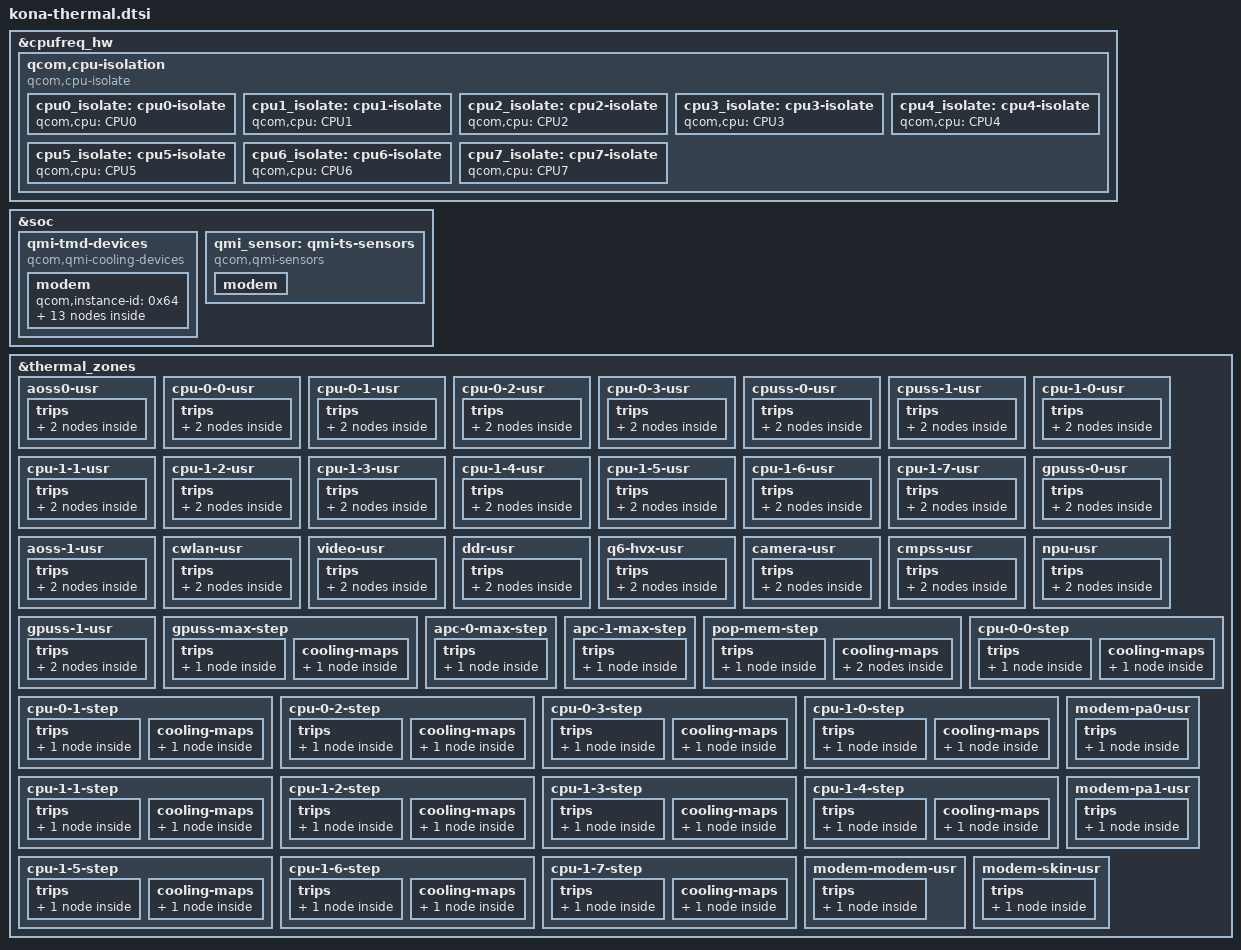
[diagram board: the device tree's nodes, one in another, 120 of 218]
// SPDX-License-Identifier: GPL-2.0-only
/*
 * Copyright (c) 2018-2019, The Linux Foundation. All rights reserved.
 */

#include <dt-bindings/thermal/thermal.h>

&cpufreq_hw {
	qcom,cpu-isolation {
		compatible = "qcom,cpu-isolate";
		cpu0_isolate: cpu0-isolate {
			qcom,cpu = <&CPU0>;
			#cooling-cells = <2>;
		};

		cpu1_isolate: cpu1-isolate {
			qcom,cpu = <&CPU1>;
			#cooling-cells = <2>;
		};

		cpu2_isolate: cpu2-isolate {
			qcom,cpu = <&CPU2>;
			#cooling-cells = <2>;
		};

		cpu3_isolate: cpu3-isolate {
			qcom,cpu = <&CPU3>;
			#cooling-cells = <2>;
		};

		cpu4_isolate: cpu4-isolate {
			qcom,cpu = <&CPU4>;
			#cooling-cells = <2>;
		};

		cpu5_isolate: cpu5-isolate {
			qcom,cpu = <&CPU5>;
			#cooling-cells = <2>;
		};

		cpu6_isolate: cpu6-isolate {
			qcom,cpu = <&CPU6>;
			#cooling-cells = <2>;
		};

		cpu7_isolate: cpu7-isolate {
			qcom,cpu = <&CPU7>;
			#cooling-cells = <2>;
		};
	};
};

&soc {
	qmi-tmd-devices {
		compatible = "qcom,qmi-cooling-devices";

		modem {
			qcom,instance-id = <0x64>;

			modem_pa: modem_pa {
				qcom,qmi-dev-name = "pa";
				#cooling-cells = <2>;
			};

			modem_proc: modem_proc {
				qcom,qmi-dev-name = "modem";
				#cooling-cells = <2>;
			};

			modem_current: modem_current {
				qcom,qmi-dev-name = "modem_current";
				#cooling-cells = <2>;
			};

			modem_skin: modem_skin {
				qcom,qmi-dev-name = "modem_skin";
				#cooling-cells = <2>;
			};

			modem_skin0: modem_skin0 {
				qcom,qmi-dev-name = "modem_skin0";
				#cooling-cells = <2>;
			};

			modem_skin1: modem_skin1 {
				qcom,qmi-dev-name = "modem_skin1";
				#cooling-cells = <2>;
			};

			modem_skin2: modem_skin2 {
				qcom,qmi-dev-name = "modem_skin2";
				#cooling-cells = <2>;
			};

			modem_skin3: modem_skin3 {
				qcom,qmi-dev-name = "modem_skin3";
				#cooling-cells = <2>;
			};

			modem_mmw0: modem_mmw0 {
				qcom,qmi-dev-name = "mmw0";
				#cooling-cells = <2>;
			};

			modem_mmw1: modem_mmw1 {
				qcom,qmi-dev-name = "mmw1";
				#cooling-cells = <2>;
			};

			modem_mmw2: modem_mmw2 {
				qcom,qmi-dev-name = "mmw2";
				#cooling-cells = <2>;
			};

			modem_mmw3: modem_mmw3 {
				qcom,qmi-dev-name = "mmw3";
				#cooling-cells = <2>;
			};

			modem_bcl: modem_bcl {
				qcom,qmi-dev-name = "vbatt_low";
				#cooling-cells = <2>;
			};
		};
	};

	qmi_sensor: qmi-ts-sensors {
		compatible = "qcom,qmi-sensors";
		#thermal-sensor-cells = <1>;

		modem {
			qcom,instance-id = <100>;
			qcom,qmi-sensor-names = "pa",
						"pa_1",
						"pa_2",
						"qfe_pa0",
						"qfe_wtr0",
						"modem_tsens",
						"qfe_mmw0",
						"qfe_mmw1",
						"qfe_mmw2",
						"qfe_mmw3",
						"xo_therm",
						"qfe_pa_mdm",
						"qfe_pa_wtr";
		};
	};
};

&thermal_zones {
	aoss0-usr {
		polling-delay-passive = <0>;
		polling-delay = <0>;
		thermal-governor = "user_space";
		thermal-sensors = <&tsens0 0>;
		trips {
			active-config0 {
				temperature = <125000>;
				hysteresis = <1000>;
				type = "passive";
			};
			active-config1 {
				temperature = <115000>;
				hysteresis = <1000>;
				type = "passive";
			};
		};
	};

	cpu-0-0-usr {
		polling-delay-passive = <0>;
		polling-delay = <0>;
		thermal-governor = "user_space";
		thermal-sensors = <&tsens0 1>;
		trips {
			active-config0 {
				temperature = <125000>;
				hysteresis = <1000>;
				type = "passive";
			};
			active-config1 {
				temperature = <115000>;
				hysteresis = <1000>;
				type = "passive";
			};
		};
	};

	cpu-0-1-usr {
		polling-delay-passive = <0>;
		polling-delay = <0>;
		thermal-governor = "user_space";
		thermal-sensors = <&tsens0 2>;
		trips {
			active-config0 {
				temperature = <125000>;
				hysteresis = <1000>;
				type = "passive";
			};
			active-config1 {
				temperature = <115000>;
				hysteresis = <1000>;
				type = "passive";
			};
		};
	};

	cpu-0-2-usr {
		polling-delay-passive = <0>;
		polling-delay = <0>;
		thermal-governor = "user_space";
		thermal-sensors = <&tsens0 3>;
		trips {
			active-config0 {
				temperature = <125000>;
				hysteresis = <1000>;
				type = "passive";
			};
			active-config1 {
				temperature = <115000>;
				hysteresis = <1000>;
				type = "passive";
			};
		};
	};

	cpu-0-3-usr {
		polling-delay-passive = <0>;
		polling-delay = <0>;
		thermal-sensors = <&tsens0 4>;
		thermal-governor = "user_space";
		trips {
			active-config0 {
				temperature = <125000>;
				hysteresis = <1000>;
				type = "passive";
			};
			active-config1 {
				temperature = <115000>;
				hysteresis = <1000>;
				type = "passive";
			};
		};
	};

	cpuss-0-usr {
		polling-delay-passive = <0>;
		polling-delay = <0>;
		thermal-sensors = <&tsens0 5>;
		thermal-governor = "user_space";
		trips {
			active-config0 {
				temperature = <125000>;
				hysteresis = <1000>;
				type = "passive";
			};
			active-config1 {
				temperature = <115000>;
				hysteresis = <1000>;
				type = "passive";
			};
		};
	};

	cpuss-1-usr {
		polling-delay-passive = <0>;
		polling-delay = <0>;
		thermal-sensors = <&tsens0 6>;
		thermal-governor = "user_space";
		trips {
			active-config0 {
				temperature = <125000>;
				hysteresis = <1000>;
				type = "passive";
			};
			active-config1 {
				temperature = <115000>;
				hysteresis = <1000>;
				type = "passive";
			};
		};
	};

	cpu-1-0-usr {
		polling-delay-passive = <0>;
		polling-delay = <0>;
		thermal-sensors = <&tsens0 7>;
		thermal-governor = "user_space";
		trips {
			active-config0 {
				temperature = <125000>;
				hysteresis = <1000>;
				type = "passive";
			};
			active-config1 {
				temperature = <115000>;
				hysteresis = <1000>;
				type = "passive";
			};
		};
	};

	cpu-1-1-usr {
		polling-delay-passive = <0>;
		polling-delay = <0>;
		thermal-sensors = <&tsens0 8>;
		thermal-governor = "user_space";
		trips {
			active-config0 {
				temperature = <125000>;
				hysteresis = <1000>;
				type = "passive";
			};
			active-config1 {
				temperature = <115000>;
				hysteresis = <1000>;
				type = "passive";
			};
		};
	};

	cpu-1-2-usr {
		polling-delay-passive = <0>;
		polling-delay = <0>;
		thermal-sensors = <&tsens0 9>;
		thermal-governor = "user_space";
		trips {
			active-config0 {
				temperature = <125000>;
				hysteresis = <1000>;
				type = "passive";
			};
			active-config1 {
				temperature = <115000>;
				hysteresis = <1000>;
				type = "passive";
			};
		};
	};

	cpu-1-3-usr {
		polling-delay-passive = <0>;
		polling-delay = <0>;
		thermal-sensors = <&tsens0 10>;
		thermal-governor = "user_space";
		trips {
			active-config0 {
				temperature = <125000>;
				hysteresis = <1000>;
				type = "passive";
			};
			active-config1 {
				temperature = <115000>;
				hysteresis = <1000>;
				type = "passive";
			};
		};
	};

	cpu-1-4-usr {
		polling-delay-passive = <0>;
		polling-delay = <0>;
		thermal-sensors = <&tsens0 11>;
		thermal-governor = "user_space";
		trips {
			active-config0 {
				temperature = <125000>;
				hysteresis = <1000>;
				type = "passive";
			};
			active-config1 {
				temperature = <115000>;
				hysteresis = <1000>;
				type = "passive";
			};
		};
	};

	cpu-1-5-usr {
		polling-delay-passive = <0>;
		polling-delay = <0>;
		thermal-sensors = <&tsens0 12>;
		thermal-governor = "user_space";
		trips {
			active-config0 {
				temperature = <125000>;
				hysteresis = <1000>;
				type = "passive";
			};
			active-config1 {
				temperature = <115000>;
				hysteresis = <1000>;
				type = "passive";
			};
		};
	};

	cpu-1-6-usr {
		polling-delay-passive = <0>;
		polling-delay = <0>;
		thermal-sensors = <&tsens0 13>;
		thermal-governor = "user_space";
		trips {
			active-config0 {
				temperature = <125000>;
				hysteresis = <1000>;
				type = "passive";
			};
			active-config1 {
				temperature = <115000>;
				hysteresis = <1000>;
				type = "passive";
			};
		};
	};

	cpu-1-7-usr {
		polling-delay-passive = <0>;
		polling-delay = <0>;
		thermal-sensors = <&tsens0 14>;
		thermal-governor = "user_space";
		trips {
			active-config0 {
				temperature = <125000>;
				hysteresis = <1000>;
				type = "passive";
			};
			active-config1 {
				temperature = <115000>;
				hysteresis = <1000>;
				type = "passive";
			};
		};
	};

	gpuss-0-usr {
		polling-delay-passive = <0>;
		polling-delay = <0>;
		thermal-sensors = <&tsens0 15>;
		thermal-governor = "user_space";
		trips {
			active-config0 {
				temperature = <125000>;
				hysteresis = <1000>;
				type = "passive";
			};
			active-config1 {
				temperature = <115000>;
				hysteresis = <1000>;
				type = "passive";
			};
		};
	};

	aoss-1-usr {
		polling-delay-passive = <0>;
		polling-delay = <0>;
		thermal-sensors = <&tsens1 0>;
		thermal-governor = "user_space";
		trips {
			active-config0 {
				temperature = <125000>;
				hysteresis = <1000>;
				type = "passive";
			};
			active-config1 {
				temperature = <115000>;
				hysteresis = <1000>;
				type = "passive";
			};
		};
	};

	cwlan-usr {
		polling-delay-passive = <0>;
		polling-delay = <0>;
		thermal-sensors = <&tsens1 1>;
		thermal-governor = "user_space";
		trips {
			active-config0 {
				temperature = <125000>;
				hysteresis = <1000>;
				type = "passive";
			};
			active-config1 {
				temperature = <115000>;
				hysteresis = <1000>;
				type = "passive";
			};
		};
	};

	video-usr {
		polling-delay-passive = <0>;
		polling-delay = <0>;
		thermal-sensors = <&tsens1 2>;
		thermal-governor = "user_space";
		trips {
			active-config0 {
				temperature = <125000>;
				hysteresis = <1000>;
				type = "passive";
			};
			active-config1 {
				temperature = <115000>;
				hysteresis = <1000>;
				type = "passive";
			};
		};
	};

	ddr-usr {
		polling-delay-passive = <0>;
		polling-delay = <0>;
		thermal-sensors = <&tsens1 3>;
		thermal-governor = "user_space";
		trips {
			active-config0 {
				temperature = <125000>;
				hysteresis = <1000>;
				type = "passive";
			};
			active-config1 {
				temperature = <115000>;
				hysteresis = <1000>;
				type = "passive";
			};
		};
	};

	q6-hvx-usr {
		polling-delay-passive = <0>;
		polling-delay = <0>;
		thermal-sensors = <&tsens1 4>;
		thermal-governor = "user_space";
		trips {
			active-config0 {
				temperature = <125000>;
				hysteresis = <1000>;
				type = "passive";
			};
			active-config1 {
				temperature = <115000>;
				hysteresis = <1000>;
				type = "passive";
			};
		};
	};

	camera-usr {
		polling-delay-passive = <0>;
		polling-delay = <0>;
		thermal-sensors = <&tsens1 5>;
		thermal-governor = "user_space";
		trips {
			active-config0 {
				temperature = <125000>;
				hysteresis = <1000>;
				type = "passive";
			};
			active-config1 {
				temperature = <115000>;
				hysteresis = <1000>;
				type = "passive";
			};
		};
	};

	cmpss-usr {
		polling-delay-passive = <0>;
		polling-delay = <0>;
		thermal-sensors = <&tsens1 6>;
		thermal-governor = "user_space";
		trips {
			active-config0 {
				temperature = <125000>;
				hysteresis = <1000>;
				type = "passive";
			};
			active-config1 {
				temperature = <115000>;
				hysteresis = <1000>;
				type = "passive";
			};
		};
	};

	npu-usr {
		polling-delay-passive = <0>;
		polling-delay = <0>;
		thermal-sensors = <&tsens1 7>;
		thermal-governor = "user_space";
		trips {
			active-config0 {
				temperature = <125000>;
				hysteresis = <1000>;
				type = "passive";
			};
			active-config1 {
				temperature = <115000>;
				hysteresis = <1000>;
				type = "passive";
			};
		};
	};

	gpuss-1-usr {
		polling-delay-passive = <0>;
		polling-delay = <0>;
		thermal-governor = "user_space";
		thermal-sensors = <&tsens1 8>;
		trips {
			active-config0 {
				temperature = <125000>;
				hysteresis = <1000>;
				type = "passive";
			};
			active-config1 {
				temperature = <115000>;
				hysteresis = <1000>;
				type = "passive";
			};
		};
	};

	gpuss-max-step {
		polling-delay-passive = <10>;
		polling-delay = <100>;
		thermal-governor = "step_wise";
		trips {
			gpu_trip0: gpu-trip0 {
				temperature = <95000>;
				hysteresis = <0>;
				type = "passive";
			};
		};

		cooling-maps {
			gpu_cdev {
				trip = <&gpu_trip0>;
				cooling-device = <&msm_gpu THERMAL_NO_LIMIT
							THERMAL_NO_LIMIT>;
			};
		};
	};

	apc-0-max-step {
		polling-delay-passive = <0>;
		polling-delay = <0>;
		thermal-governor = "step_wise";
		trips {
			silver-trip {
				temperature = <120000>;
				hysteresis = <0>;
				type = "passive";
			};
		};
	};

	apc-1-max-step {
		polling-delay-passive = <0>;
		polling-delay = <0>;
		thermal-governor = "step_wise";
		trips {
			gold-trip {
				temperature = <120000>;
				hysteresis = <0>;
				type = "passive";
			};
		};
	};

	pop-mem-step {
		polling-delay-passive = <10>;
		polling-delay = <0>;
		thermal-sensors = <&tsens1 3>;
		thermal-governor = "step_wise";
		trips {
			pop_trip: pop-trip {
				temperature = <95000>;
				hysteresis = <0>;
				type = "passive";
			};
		};

		cooling-maps {
			pop_cdev4 {
				trip = <&pop_trip>;
				cooling-device =
					<&CPU4 THERMAL_NO_LIMIT
						THERMAL_NO_LIMIT>;
			};

			pop_cdev7 {
				trip = <&pop_trip>;
				cooling-device =
					<&CPU7 THERMAL_NO_LIMIT
						THERMAL_NO_LIMIT>;
			};
		};
	};

	cpu-0-0-step {
		polling-delay-passive = <0>;
		polling-delay = <0>;
		thermal-governor = "step_wise";
		thermal-sensors = <&tsens0 1>;
		trips {
			cpu00_config: cpu00-config {
				temperature = <110000>;
				hysteresis = <10000>;
				type = "passive";
			};
		};

		cooling-maps {
			cpu00_cdev {
				trip = <&cpu00_config>;
				cooling-device = <&cpu0_isolate 1 1>;
			};
		};
	};

	cpu-0-1-step {
		polling-delay-passive = <0>;
		polling-delay = <0>;
		thermal-governor = "step_wise";
		thermal-sensors = <&tsens0 2>;
		trips {
			cpu01_config: cpu01-config {
				temperature = <110000>;
				hysteresis = <10000>;
				type = "passive";
			};
		};

		cooling-maps {
			cpu01_cdev {
				trip = <&cpu01_config>;
				cooling-device = <&cpu1_isolate 1 1>;
			};
		};
	};

	cpu-0-2-step {
		polling-delay-passive = <0>;
		polling-delay = <0>;
		thermal-governor = "step_wise";
		thermal-sensors = <&tsens0 3>;
		trips {
			cpu02_config: cpu02-config {
				temperature = <110000>;
				hysteresis = <10000>;
				type = "passive";
			};
		};

		cooling-maps {
			cpu02_cdev {
				trip = <&cpu02_config>;
				cooling-device = <&cpu2_isolate 1 1>;
			};
		};
	};

	cpu-0-3-step {
		polling-delay-passive = <0>;
		polling-delay = <0>;
		thermal-sensors = <&tsens0 4>;
		thermal-governor = "step_wise";
		trips {
			cpu03_config: cpu03-config {
				temperature = <110000>;
				hysteresis = <10000>;
				type = "passive";
			};
		};

		cooling-maps {
			cpu03_cdev {
				trip = <&cpu03_config>;
				cooling-device = <&cpu3_isolate 1 1>;
			};
		};
	};

	cpu-1-0-step {
		polling-delay-passive = <0>;
		polling-delay = <0>;
		thermal-sensors = <&tsens0 7>;
		thermal-governor = "step_wise";
		trips {
			cpu10_config: cpu10-config {
				temperature = <110000>;
				hysteresis = <10000>;
				type = "passive";
			};
		};

		cooling-maps {
			cpu10_cdev {
				trip = <&cpu10_config>;
				cooling-device = <&cpu4_isolate 1 1>;
			};
		};
	};

	cpu-1-1-step {
		polling-delay-passive = <0>;
		polling-delay = <0>;
		thermal-sensors = <&tsens0 8>;
		thermal-governor = "step_wise";
		trips {
			cpu11_config: cpu11-config {
				temperature = <110000>;
				hysteresis = <10000>;
				type = "passive";
			};
		};

		cooling-maps {
			cpu11_cdev {
				trip = <&cpu11_config>;
				cooling-device = <&cpu5_isolate 1 1>;
			};
		};
	};

	cpu-1-2-step {
		polling-delay-passive = <0>;
		polling-delay = <0>;
		thermal-sensors = <&tsens0 9>;
		thermal-governor = "step_wise";
		trips {
			cpu12_config: cpu12-config {
				temperature = <110000>;
				hysteresis = <10000>;
				type = "passive";
			};
		};

		cooling-maps {
			cpu12_cdev {
				trip = <&cpu12_config>;
				cooling-device = <&cpu6_isolate 1 1>;
			};
		};
	};

	cpu-1-3-step {
		polling-delay-passive = <0>;
		polling-delay = <0>;
		thermal-sensors = <&tsens0 10>;
		thermal-governor = "step_wise";
		trips {
			cpu13_config: cpu13-config {
				temperature = <110000>;
				hysteresis = <10000>;
				type = "passive";
			};
		};

		cooling-maps {
			cpu13_cdev {
				trip = <&cpu13_config>;
				cooling-device = <&cpu7_isolate 1 1>;
			};
		};
	};

	cpu-1-4-step {
		polling-delay-passive = <0>;
		polling-delay = <0>;
		thermal-sensors = <&tsens0 11>;
		thermal-governor = "step_wise";
		trips {
			cpu14_config: cpu14-config {
				temperature = <110000>;
				hysteresis = <10000>;
				type = "passive";
			};
		};

		cooling-maps {
			cpu14_cdev {
				trip = <&cpu14_config>;
				cooling-device = <&cpu4_isolate 1 1>;
			};
		};
	};

	cpu-1-5-step {
		polling-delay-passive = <0>;
		polling-delay = <0>;
		thermal-sensors = <&tsens0 12>;
		thermal-governor = "step_wise";
		trips {
			cpu15_config: cpu15-config {
				temperature = <110000>;
				hysteresis = <10000>;
				type = "passive";
			};
		};

		cooling-maps {
			cpu15_cdev {
				trip = <&cpu15_config>;
				cooling-device = <&cpu5_isolate 1 1>;
			};
		};
	};

	cpu-1-6-step {
		polling-delay-passive = <0>;
		polling-delay = <0>;
		thermal-sensors = <&tsens0 13>;
		thermal-governor = "step_wise";
		trips {
			cpu16_config: cpu16-config {
				temperature = <110000>;
				hysteresis = <10000>;
				type = "passive";
			};
		};

		cooling-maps {
			cpu16_cdev {
				trip = <&cpu16_config>;
				cooling-device = <&cpu6_isolate 1 1>;
			};
		};
	};

	cpu-1-7-step {
		polling-delay-passive = <0>;
		polling-delay = <0>;
		thermal-sensors = <&tsens0 14>;
		thermal-governor = "step_wise";
		trips {
			cpu17_config: cpu17-config {
				temperature = <110000>;
				hysteresis = <10000>;
				type = "passive";
			};
		};

		cooling-maps {
			cpu17_cdev {
				trip = <&cpu17_config>;
				cooling-device = <&cpu7_isolate 1 1>;
			};
		};
	};

	modem-pa0-usr {
		polling-delay-passive = <0>;
		polling-delay = <0>;
		thermal-governor = "user_space";
		thermal-sensors = <&qmi_sensor 100>;
		trips {
			active-config0 {
				temperature = <125000>;
				hysteresis = <1000>;
				type = "passive";
			};
		};
	};

	modem-pa1-usr {
		polling-delay-passive = <0>;
		polling-delay = <0>;
		thermal-governor = "user_space";
		thermal-sensors = <&qmi_sensor 101>;
		trips {
			active-config0 {
				temperature = <125000>;
				hysteresis = <1000>;
				type = "passive";
			};
		};
	};

	modem-modem-usr {
		polling-delay-passive = <0>;
		polling-delay = <0>;
		thermal-governor = "user_space";
		thermal-sensors = <&qmi_sensor 105>;
		trips {
			active-config0 {
				temperature = <125000>;
				hysteresis = <1000>;
				type = "passive";
			};
		};
	};

	modem-skin-usr {
		polling-delay-passive = <0>;
		polling-delay = <0>;
		thermal-governor = "user_space";
		thermal-sensors = <&qmi_sensor 110>;
		trips {
			active-config0 {
				temperature = <125000>;
				hysteresis = <1000>;
				type = "passive";
			};
		};
	};
};
